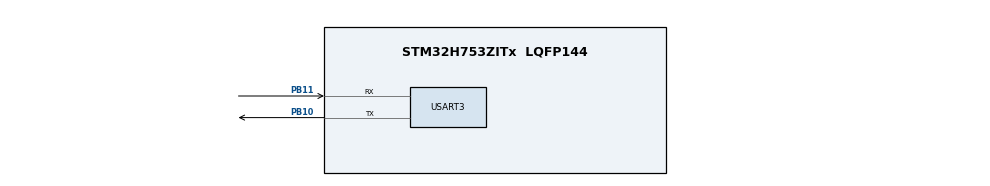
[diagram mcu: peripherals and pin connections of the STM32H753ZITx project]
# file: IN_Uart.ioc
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CORTEX_M7.CPU_DCache=Disabled
CORTEX_M7.CPU_ICache=Disabled
CORTEX_M7.MPU_Control=__NULL
CORTEX_M7.default_mode_Activation=1
Mcu.Family=STM32H7
Mcu.Name=STM32H753ZITx
Mcu.Package=LQFP144
NVIC.PriorityGroup=NVIC_PRIORITYGROUP_4
NVIC.USART3_IRQn=true\:0\:0\:false\:false\:true\:true\:true\:true
PB0.TagName=LD1
PB10.Mode=Asynchronous
PB10.Signal=USART3_TX
PB11.GPIO_PuPd=GPIO_PULLUP
PB11.Mode=Asynchronous
PB11.Signal=USART3_RX
PB14.TagName=LD3
PB7.TagName=LD2
PC13.TagName=BUTTON
PD8.TagName=VCP_TX
PD9.TagName=VCP_RX
ProjectManager.HeapSize=0x200
ProjectManager.StackSize=0x400
ProjectManager.TargetToolchain=STM32CubeIDE
RCC.ADCFreq_Value=129000000
RCC.APB1Freq_Value=64000000
RCC.APB2Freq_Value=64000000
RCC.APB3Freq_Value=64000000
RCC.APB4Freq_Value=64000000
RCC.CortexFreq_Value=64000000
RCC.DIVM1=1
RCC.DIVN1=24
RCC.DIVQ1=4
RCC.HCLKFreq_Value=64000000
RCC.HSE_VALUE=8000000
RCC.PLLFRACN=0
RCC.PWR_Regulator_Voltage_Scale=PWR_REGULATOR_VOLTAGE_SCALE2
RCC.SYSCLKFreq_VALUE=64000000
RCC.USBFreq_Value=384000000
USART3.VirtualMode-Asynchronous=VM_ASYNC
VP_MEMORYMAP_VS_MEMORYMAP.Mode=CurAppReg
board=NUCLEO-H753ZI

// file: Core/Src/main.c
/* USER CODE BEGIN Header */
/**
  ******************************************************************************
  * @file           : main.c
  * @brief          : Main program body
  ******************************************************************************
  * @attention
  *
  * Copyright (c) 2026 STMicroelectronics.
  * All rights reserved.
  *
  * This software is licensed under terms that can be found in the LICENSE file
  * in the root directory of this software component.
  * If no LICENSE file comes with this software, it is provided AS-IS.
  *
  ******************************************************************************
  */
/* USER CODE END Header */
#include "main.h"

UART_HandleTypeDef huart3;

/* USER CODE BEGIN PV */
uint8_t rxByte;                     // receives 1 byte at a time
uint8_t rxBuf[128];
volatile uint16_t rxIdx = 0;

uint8_t txMsg[] = "UART Interrupt Ready\r\nType something...\r\n";
/* USER CODE END PV */

void SystemClock_Config(void);
static void MX_GPIO_Init(void);
static void MX_USART3_UART_Init(void);

int main(void)
{

  /* MCU Configuration--------------------------------------------------------*/

  /* Reset of all peripherals, Initializes the Flash interface and the Systick. */
  HAL_Init();

  /* Configure the system clock */
  SystemClock_Config();

  /* Initialize all configured peripherals */
  MX_GPIO_Init();
  MX_USART3_UART_Init();

  /* USER CODE BEGIN 2 */
  HAL_UART_Transmit_IT(&huart3, txMsg, sizeof(txMsg) - 1);

  // Start 1-byte interrupt receive
  HAL_UART_Receive_IT(&huart3, &rxByte, 1);
  /* USER CODE END 2 */

  /* Infinite loop */
  while (1)
  {

  }
}

void SystemClock_Config(void)
{
  RCC_OscInitTypeDef RCC_OscInitStruct = {0};
  RCC_ClkInitTypeDef RCC_ClkInitStruct = {0};

  /** Supply configuration update enable
  */
  HAL_PWREx_ConfigSupply(PWR_LDO_SUPPLY);

  /** Configure the main internal regulator output voltage
  */
  __HAL_PWR_VOLTAGESCALING_CONFIG(PWR_REGULATOR_VOLTAGE_SCALE2);

  while(!__HAL_PWR_GET_FLAG(PWR_FLAG_VOSRDY)) {}

  /** Initializes the RCC Oscillators according to the specified parameters
  * in the RCC_OscInitTypeDef structure.
  */
  RCC_OscInitStruct.OscillatorType = RCC_OSCILLATORTYPE_HSI;
  RCC_OscInitStruct.HSIState = RCC_HSI_DIV1;
  RCC_OscInitStruct.HSICalibrationValue = RCC_HSICALIBRATION_DEFAULT;
  RCC_OscInitStruct.PLL.PLLState = RCC_PLL_NONE;
  if (HAL_RCC_OscConfig(&RCC_OscInitStruct) != HAL_OK)
  {
    Error_Handler();
  }

  /** Initializes the CPU, AHB and APB buses clocks
  */
  RCC_ClkInitStruct.ClockType = RCC_CLOCKTYPE_HCLK|RCC_CLOCKTYPE_SYSCLK
                              |RCC_CLOCKTYPE_PCLK1|RCC_CLOCKTYPE_PCLK2
                              |RCC_CLOCKTYPE_D3PCLK1|RCC_CLOCKTYPE_D1PCLK1;
  RCC_ClkInitStruct.SYSCLKSource = RCC_SYSCLKSOURCE_HSI;
  RCC_ClkInitStruct.SYSCLKDivider = RCC_SYSCLK_DIV1;
  RCC_ClkInitStruct.AHBCLKDivider = RCC_HCLK_DIV1;
  RCC_ClkInitStruct.APB3CLKDivider = RCC_APB3_DIV1;
  RCC_ClkInitStruct.APB1CLKDivider = RCC_APB1_DIV1;
  RCC_ClkInitStruct.APB2CLKDivider = RCC_APB2_DIV1;
  RCC_ClkInitStruct.APB4CLKDivider = RCC_APB4_DIV1;

  if (HAL_RCC_ClockConfig(&RCC_ClkInitStruct, FLASH_LATENCY_1) != HAL_OK)
  {
    Error_Handler();
  }
}

static void MX_USART3_UART_Init(void)
{

  huart3.Instance = USART3;
  huart3.Init.BaudRate = 115200;
  huart3.Init.WordLength = UART_WORDLENGTH_8B;
  huart3.Init.StopBits = UART_STOPBITS_1;
  huart3.Init.Parity = UART_PARITY_NONE;
  huart3.Init.Mode = UART_MODE_TX_RX;
  huart3.Init.HwFlowCtl = UART_HWCONTROL_NONE;
  huart3.Init.OverSampling = UART_OVERSAMPLING_16;
  huart3.Init.OneBitSampling = UART_ONE_BIT_SAMPLE_DISABLE;
  huart3.Init.ClockPrescaler = UART_PRESCALER_DIV1;
  huart3.AdvancedInit.AdvFeatureInit = UART_ADVFEATURE_NO_INIT;
  if (HAL_UART_Init(&huart3) != HAL_OK)
  {
    Error_Handler();
  }
  if (HAL_UARTEx_SetTxFifoThreshold(&huart3, UART_TXFIFO_THRESHOLD_1_8) != HAL_OK)
  {
    Error_Handler();
  }
  if (HAL_UARTEx_SetRxFifoThreshold(&huart3, UART_RXFIFO_THRESHOLD_1_8) != HAL_OK)
  {
    Error_Handler();
  }
  if (HAL_UARTEx_DisableFifoMode(&huart3) != HAL_OK)
  {
    Error_Handler();
  }

}

static void MX_GPIO_Init(void)
{

  /* GPIO Ports Clock Enable */
  __HAL_RCC_GPIOB_CLK_ENABLE();

}

/* USER CODE BEGIN 4 */
void HAL_UART_RxCpltCallback(UART_HandleTypeDef *huart)
{
  if (huart->Instance == USART3)
  {
    // Store byte
    if (rxIdx < sizeof(rxBuf) - 1)
    {
      rxBuf[rxIdx++] = rxByte;
    }

    // Echo back the received byte (interrupt TX)
    HAL_UART_Transmit_IT(&huart3, &rxByte, 1);

    // If user pressed Enter (CR or LF), print new line + reset buffer
    if (rxByte == '\r' || rxByte == '\n')
    {
      uint8_t nl[] = "\r\n";
      HAL_UART_Transmit_IT(&huart3, nl, sizeof(nl) - 1);

      rxIdx = 0;
    }

    // Re-arm reception for next byte (THIS IS REQUIRED)
    HAL_UART_Receive_IT(&huart3, &rxByte, 1);
  }
}

void HAL_UART_ErrorCallback(UART_HandleTypeDef *huart)
{
  if (huart->Instance == USART3)
  {
    // Clear error by restarting receive
    HAL_UART_Receive_IT(&huart3, &rxByte, 1);
  }
}
/* USER CODE END 4 */

void Error_Handler(void)
{
  __disable_irq();
  while (1)
  {
  }
}
